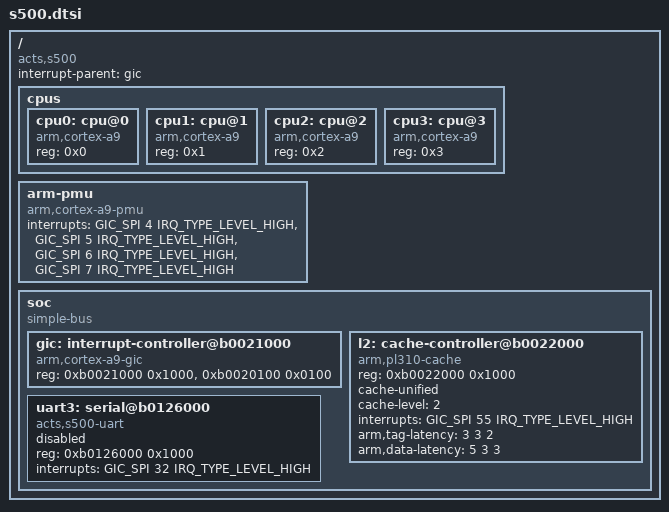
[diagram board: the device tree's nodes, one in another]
/*
 * Actions Semi S500 SoC
 *
 * Copyright (c) 2016-2017 Andreas Färber
 *
 * This file is dual-licensed: you can use it either under the terms
 * of the GPL or the X11 license, at your option. Note that this dual
 * licensing only applies to this file, and not this project as a
 * whole.
 *
 *  a) This library is free software; you can redistribute it and/or
 *     modify it under the terms of the GNU General Public License as
 *     published by the Free Software Foundation; either version 2 of the
 *     License, or (at your option) any later version.
 *
 *     This library is distributed in the hope that it will be useful,
 *     but WITHOUT ANY WARRANTY; without even the implied warranty of
 *     MERCHANTABILITY or FITNESS FOR A PARTICULAR PURPOSE.  See the
 *     GNU General Public License for more details.
 *
 * Or, alternatively,
 *
 *  b) Permission is hereby granted, free of charge, to any person
 *     obtaining a copy of this software and associated documentation
 *     files (the "Software"), to deal in the Software without
 *     restriction, including without limitation the rights to use,
 *     copy, modify, merge, publish, distribute, sublicense, and/or
 *     sell copies of the Software, and to permit persons to whom the
 *     Software is furnished to do so, subject to the following
 *     conditions:
 *
 *     The above copyright notice and this permission notice shall be
 *     included in all copies or substantial portions of the Software.
 *
 *     THE SOFTWARE IS PROVIDED "AS IS", WITHOUT WARRANTY OF ANY KIND,
 *     EXPRESS OR IMPLIED, INCLUDING BUT NOT LIMITED TO THE WARRANTIES
 *     OF MERCHANTABILITY, FITNESS FOR A PARTICULAR PURPOSE AND
 *     NONINFRINGEMENT. IN NO EVENT SHALL THE AUTHORS OR COPYRIGHT
 *     HOLDERS BE LIABLE FOR ANY CLAIM, DAMAGES OR OTHER LIABILITY,
 *     WHETHER IN AN ACTION OF CONTRACT, TORT OR OTHERWISE, ARISING
 *     FROM, OUT OF OR IN CONNECTION WITH THE SOFTWARE OR THE USE OR
 *     OTHER DEALINGS IN THE SOFTWARE.
 */

#include "skeleton.dtsi"

#include <dt-bindings/interrupt-controller/irq.h>
#include <dt-bindings/interrupt-controller/arm-gic.h>

/ {
	compatible = "acts,s500";
	interrupt-parent = <&gic>;

	cpus {
		#address-cells = <1>;
		#size-cells = <0>;

		cpu0: cpu@0 {
			compatible = "arm,cortex-a9";
			reg = <0x0>;
		};

		cpu1: cpu@1 {
			compatible = "arm,cortex-a9";
			reg = <0x1>;
		};

		cpu2: cpu@2 {
			compatible = "arm,cortex-a9";
			reg = <0x2>;
		};

		cpu3: cpu@3 {
			compatible = "arm,cortex-a9";
			reg = <0x3>;
		};
	};

	arm-pmu {
		compatible = "arm,cortex-a9-pmu";
		interrupts = <GIC_SPI 4 IRQ_TYPE_LEVEL_HIGH>,
		             <GIC_SPI 5 IRQ_TYPE_LEVEL_HIGH>,
		             <GIC_SPI 6 IRQ_TYPE_LEVEL_HIGH>,
		             <GIC_SPI 7 IRQ_TYPE_LEVEL_HIGH>;
        };

	soc {
		compatible = "simple-bus";
		#address-cells = <1>;
		#size-cells = <1>;
		ranges;

		gic: interrupt-controller@b0021000 {
			compatible = "arm,cortex-a9-gic";
			reg = <0xb0021000 0x1000>,
			      <0xb0020100 0x0100>;
		};

		l2: cache-controller@b0022000 {
			compatible = "arm,pl310-cache";
			reg = <0xb0022000 0x1000>;
			cache-unified;
			cache-level = <2>;
			interrupts = <GIC_SPI 55 IRQ_TYPE_LEVEL_HIGH>;
			arm,tag-latency = <3 3 2>;
			arm,data-latency = <5 3 3>;
		};

		uart3: serial@b0126000 {
			compatible = "acts,s500-uart", "acts,owl-uart";
			reg = <0xb0126000 0x1000>;
			interrupts = <GIC_SPI 32 IRQ_TYPE_LEVEL_HIGH>;
			status = "disabled";
		};
	};
};
